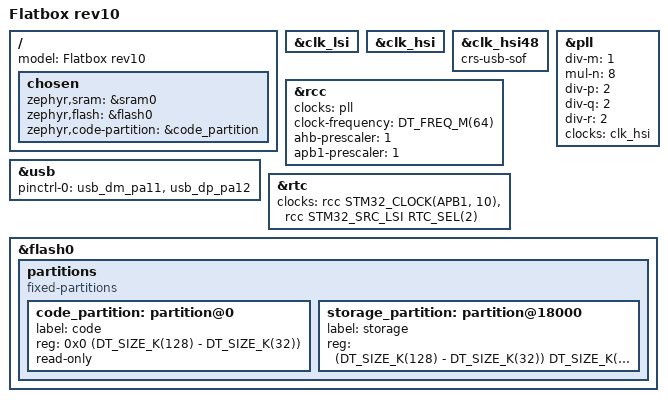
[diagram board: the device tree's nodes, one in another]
/dts-v1/;
#include <st/g0/stm32g0b1Xb.dtsi>
#include <st/g0/stm32g0b1k(b-c-e)ux-pinctrl.dtsi>

/ {
    model = "Flatbox rev10";

    chosen {
        zephyr,sram = &sram0;
        zephyr,flash = &flash0;
        zephyr,code-partition = &code_partition;
    };
};

&clk_lsi {
    status = "okay";
};

&clk_hsi {
    status = "okay";
};

&clk_hsi48 {
    status = "okay";
    crs-usb-sof;
};

&pll {
    div-m = <1>;
    mul-n = <8>;
    div-p = <2>;
    div-q = <2>;
    div-r = <2>;
    clocks = <&clk_hsi>;
    status = "okay";
};

&rcc {
    clocks = <&pll>;
    clock-frequency = <DT_FREQ_M(64)>;
    ahb-prescaler = <1>;
    apb1-prescaler = <1>;
};

zephyr_udc0: &usb {
    pinctrl-0 = <&usb_dm_pa11 &usb_dp_pa12>;
    pinctrl-names = "default";
    status = "okay";
};

&rtc {
    clocks = <&rcc STM32_CLOCK(APB1, 10)>,
         <&rcc STM32_SRC_LSI RTC_SEL(2)>;
    status = "okay";
};


&flash0 {
    partitions {
        compatible = "fixed-partitions";
        #address-cells = <1>;
        #size-cells = <1>;

        code_partition: partition@0 {
            label = "code";
            reg = <0x0 (DT_SIZE_K(128) - DT_SIZE_K(32))>;
            read-only;
        };

        storage_partition: partition@18000 {
            label = "storage";
            reg = <(DT_SIZE_K(128) - DT_SIZE_K(32)) DT_SIZE_K(32)>;
        };
    };
};
